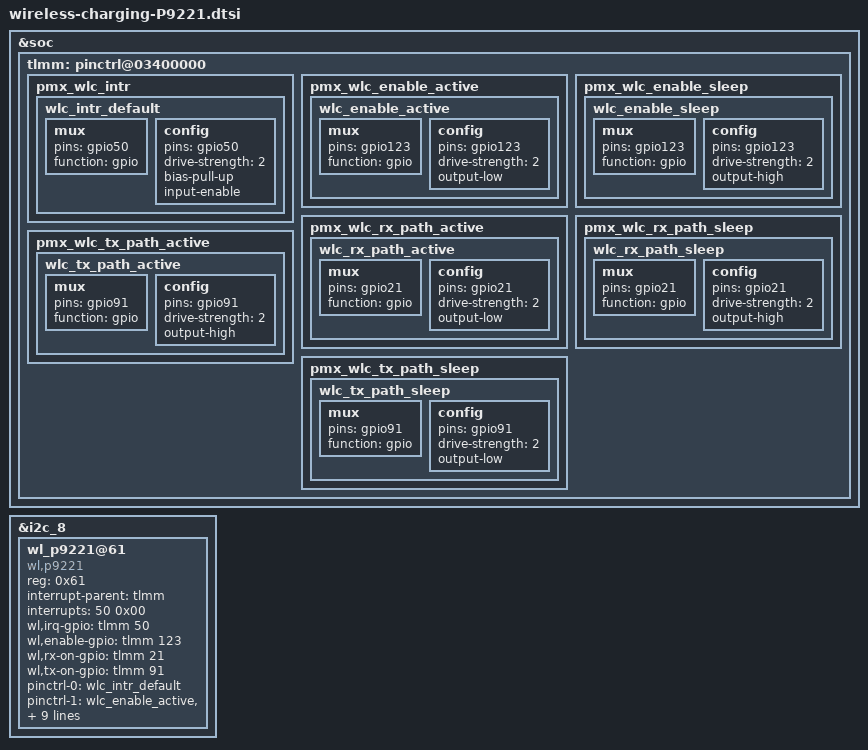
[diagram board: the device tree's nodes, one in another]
&soc {
	tlmm: pinctrl@03400000 {
		pmx_wlc_intr {
			wlc_intr_default: wlc_intr_default {
				mux {
					pins = "gpio50";
					function = "gpio";
				};

				config {
					pins = "gpio50";
					drive-strength = <2>; /* 2 mA */
					bias-pull-up; /* pull up */
					input-enable;
				};
			};
		};


		pmx_wlc_enable_active {
			wlc_enable_active: wlc_enable_active {
				mux {
					pins = "gpio123";
					function = "gpio";
				};

				config {
					pins = "gpio123";
					drive-strength = <2>; /* 2 mA */
					output-low;
				};
			};
		};

		pmx_wlc_enable_sleep {
			wlc_enable_sleep: wlc_enable_sleep {
				mux {
					pins = "gpio123";
					function = "gpio";
				};

				config {
					pins = "gpio123";
					drive-strength = <2>; /* 2 mA */
					output-high;
				};
			};
		};


		pmx_wlc_rx_path_active {
			wlc_rx_path_active: wlc_rx_path_active {
				mux {
					pins = "gpio21";
					function = "gpio";
				};

				config {
					pins = "gpio21";
					drive-strength = <2>; /* 2 mA */
					output-low;
				};
			};
		};

		pmx_wlc_rx_path_sleep {
			wlc_rx_path_sleep: wlc_rx_path_sleep {
				mux {
					pins = "gpio21";
					function = "gpio";
				};

				config {
					pins = "gpio21";
					drive-strength = <2>; /* 2 mA */
					output-high;
				};
			};
		};


		pmx_wlc_tx_path_active {
			wlc_tx_path_active: wlc_tx_path_active {
				mux {
					pins = "gpio91";
					function = "gpio";
				};

				config {
					pins = "gpio91";
					drive-strength = <2>; /* 2 mA */
					output-high;
				};
			};
		};

		pmx_wlc_tx_path_sleep {
			wlc_tx_path_sleep: wlc_tx_path_sleep {
				mux {
					pins = "gpio91";
					function = "gpio";
				};

				config {
					pins = "gpio91";
					drive-strength = <2>; /* 2 mA */
					output-low;
				};
			};
		};
	};
};

&i2c_8{
		status = "ok";
		wl_p9221@61 {
			compatible = "wl,p9221";
			reg = <0x61>;
			interrupt-parent = <&tlmm>;
			interrupts = <50 0x00>;
			wl,irq-gpio = <&tlmm 50 0x00>;
			wl,enable-gpio = <&tlmm 123 0x00>;
			wl,rx-on-gpio = <&tlmm 21 0x00>;
			wl,tx-on-gpio = <&tlmm 91 0x00>;
			pinctrl-names = "pmx_wlc_intr_active",
				"pmx_wlc_rx_path_active", "pmx_wlc_rx_path_sleep",
				"pmx_wlc_tx_path_active", "pmx_wlc_tx_path_sleep",
				"pmx_wlc_sleep";
			pinctrl-0 = <&wlc_intr_default>;
			pinctrl-1 = <&wlc_enable_active &wlc_rx_path_active>;
			pinctrl-2 = <&wlc_enable_active &wlc_rx_path_sleep>;
			pinctrl-3 = <&wlc_enable_active &wlc_tx_path_active>;
			pinctrl-4 = <&wlc_enable_active &wlc_tx_path_sleep>;
			pinctrl-5 = <&wlc_enable_sleep &wlc_tx_path_sleep &wlc_rx_path_active>;
		};
};
